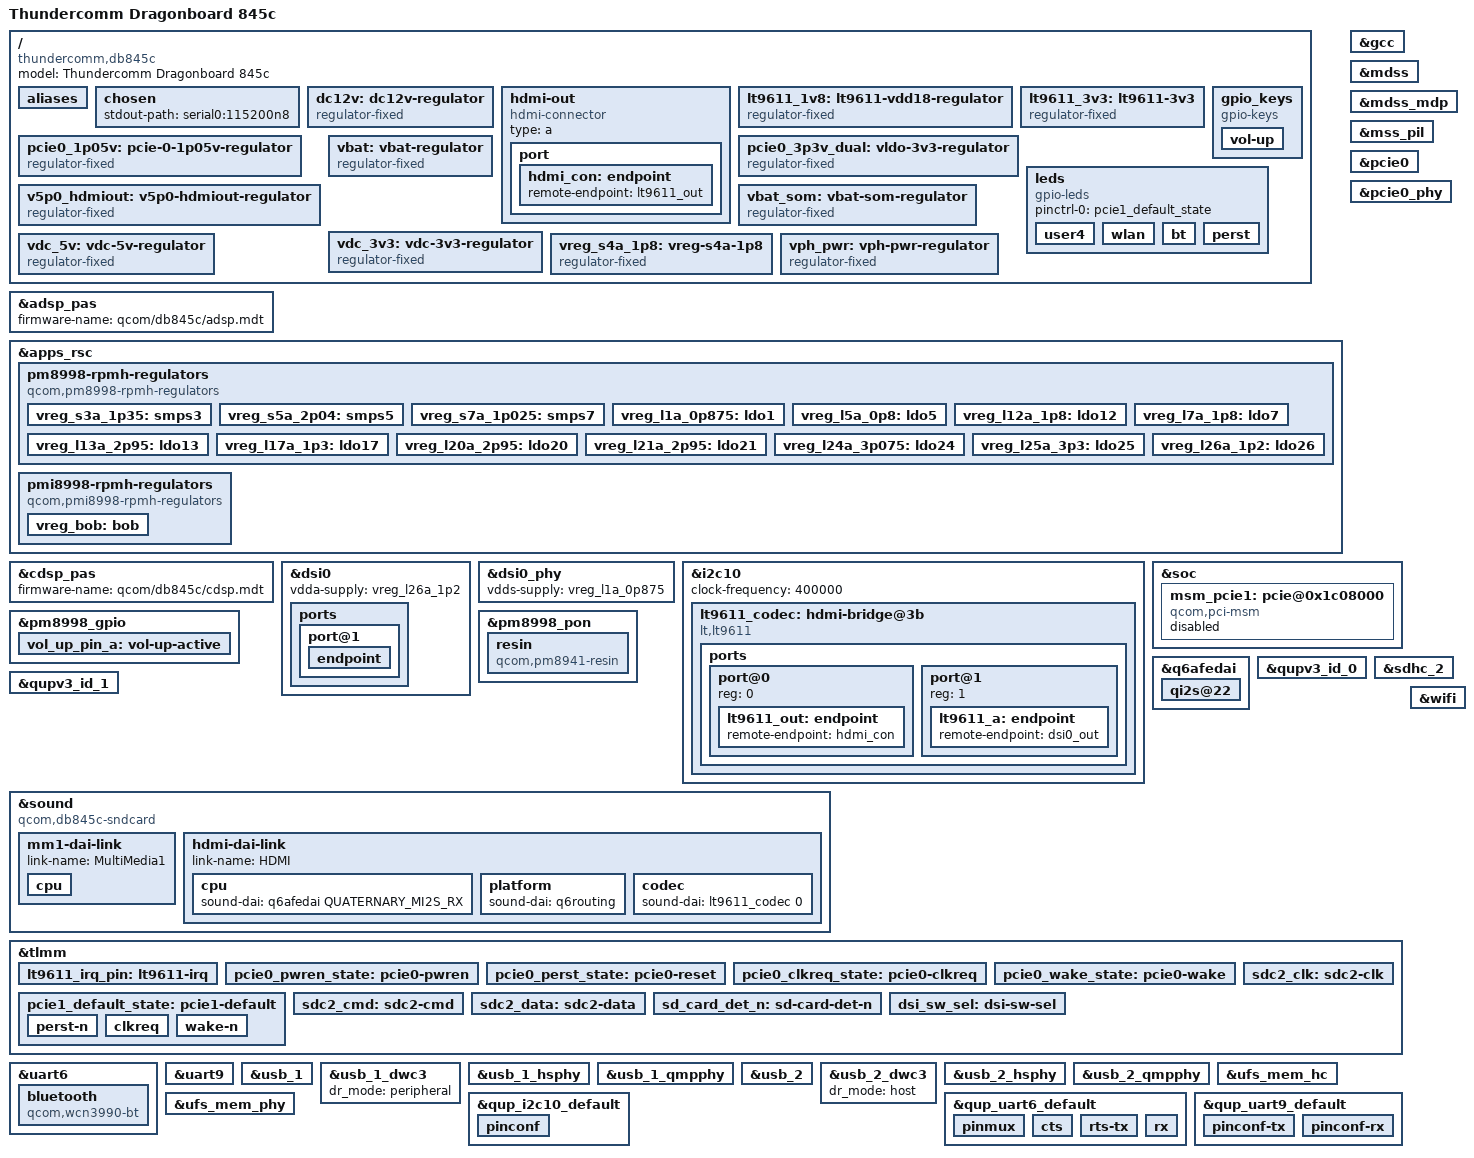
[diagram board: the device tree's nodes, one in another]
// SPDX-License-Identifier: GPL-2.0

/dts-v1/;

#include <dt-bindings/gpio/gpio.h>
#include <dt-bindings/pinctrl/qcom,pmic-gpio.h>
#include <dt-bindings/regulator/qcom,rpmh-regulator.h>
#include <dt-bindings/sound/qcom,q6afe.h>
#include <dt-bindings/sound/qcom,q6asm.h>
#include "sdm845.dtsi"
#include "pm8998.dtsi"
#include "pmi8998.dtsi"

/ {
	model = "Thundercomm Dragonboard 845c";
	compatible = "thundercomm,db845c", "qcom,sdm845";

	aliases {
		serial0 = &uart9;
		hsuart0 = &uart6;
	};

	chosen {
		stdout-path = "serial0:115200n8";
	};

	dc12v: dc12v-regulator {
		compatible = "regulator-fixed";
		regulator-name = "DC12V";
		regulator-min-microvolt = <12000000>;
		regulator-max-microvolt = <12000000>;
		regulator-always-on;
	};

	hdmi-out {
		compatible = "hdmi-connector";
		type = "a";

		port {
			hdmi_con: endpoint {
				remote-endpoint = <&lt9611_out>;
			};
		};
	};

	lt9611_1v8: lt9611-vdd18-regulator {
		compatible = "regulator-fixed";
		regulator-name = "LT9611_1V8";

		vin-supply = <&vdc_5v>;
		regulator-min-microvolt = <1800000>;
		regulator-max-microvolt = <1800000>;

		gpio = <&tlmm 89 GPIO_ACTIVE_HIGH>;
		enable-active-high;
	};

	lt9611_3v3: lt9611-3v3 {
		compatible = "regulator-fixed";
		regulator-name = "LT9611_3V3";

		vin-supply = <&vdc_3v3>;
		regulator-min-microvolt = <3300000>;
		regulator-max-microvolt = <3300000>;

		// TODO: make it possible to drive same GPIO from two clients
		// gpio = <&tlmm 89 GPIO_ACTIVE_HIGH>;
		// enable-active-high;
	};

	pcie0_1p05v: pcie-0-1p05v-regulator {
		compatible = "regulator-fixed";
		regulator-name = "PCIE0_1.05V";

		vin-supply = <&vbat>;
		regulator-min-microvolt = <1050000>;
		regulator-max-microvolt = <1050000>;

		// TODO: make it possible to drive same GPIO from two clients
		// gpio = <&tlmm 90 GPIO_ACTIVE_HIGH>;
		// enable-active-high;
	};

	pcie0_3p3v_dual: vldo-3v3-regulator {
		compatible = "regulator-fixed";
		regulator-name = "VLDO_3V3";

		vin-supply = <&vbat>;
		regulator-min-microvolt = <3300000>;
		regulator-max-microvolt = <3300000>;

		gpio = <&tlmm 90 GPIO_ACTIVE_HIGH>;
		enable-active-high;
	};

	gpio_keys {
		compatible = "gpio-keys";
		#address-cells = <1>;
		#size-cells = <0>;
		autorepeat;

		pinctrl-names = "default";
		pinctrl-0 = <&vol_up_pin_a>;

		vol-up {
			label = "Volume Up";
			linux,code = <KEY_VOLUMEUP>;
			gpios = <&pm8998_gpio 6 GPIO_ACTIVE_LOW>;
		};
	};

	leds {
		compatible = "gpio-leds";

		pinctrl-names = "default";
		pinctrl-0 = <&pcie1_default_state>;

		user4 {
			label = "db845c:green:user4";
			gpios = <&pm8998_gpio 13 GPIO_ACTIVE_HIGH>;
			linux,default-trigger = "heartbeat";
			default-state = "off";
		};

		wlan {
			label = "db845c:yellow:wlan";
			gpios = <&pm8998_gpio 9 GPIO_ACTIVE_HIGH>;
			linux,default-trigger = "phy0tx";
			default-state = "off";
		};

		bt {
			label = "db845c:blue:bt";
			gpios = <&pm8998_gpio 5 GPIO_ACTIVE_HIGH>;
			linux,default-trigger = "bluetooth-power";
			default-state = "off";
		};

		perst {
			label = "perst";
			gpios = <&tlmm 102 GPIO_ACTIVE_HIGH>;
			linux,default-trigger = "heartbeat";
			default-state = "off";
		};
	};

	v5p0_hdmiout: v5p0-hdmiout-regulator {
		compatible = "regulator-fixed";
		regulator-name = "V5P0_HDMIOUT";

		vin-supply = <&vdc_5v>;
		regulator-min-microvolt = <500000>;
		regulator-max-microvolt = <500000>;

		// TODO: make it possible to drive same GPIO from two clients
		// gpio = <&tlmm 89 GPIO_ACTIVE_HIGH>;
		// enable-active-high;
	};

	vbat: vbat-regulator {
		compatible = "regulator-fixed";
		regulator-name = "VBAT";

		vin-supply = <&dc12v>;
		regulator-min-microvolt = <4200000>;
		regulator-max-microvolt = <4200000>;
		regulator-always-on;
	};

	vbat_som: vbat-som-regulator {
		compatible = "regulator-fixed";
		regulator-name = "VBAT_SOM";

		vin-supply = <&dc12v>;
		regulator-min-microvolt = <4200000>;
		regulator-max-microvolt = <4200000>;
		regulator-always-on;
	};

	vdc_3v3: vdc-3v3-regulator {
		compatible = "regulator-fixed";
		regulator-name = "VDC_3V3";
		vin-supply = <&dc12v>;
		regulator-min-microvolt = <3300000>;
		regulator-max-microvolt = <3300000>;
		regulator-always-on;
	};

	vdc_5v: vdc-5v-regulator {
		compatible = "regulator-fixed";
		regulator-name = "VDC_5V";

		vin-supply = <&dc12v>;
		regulator-min-microvolt = <500000>;
		regulator-max-microvolt = <500000>;
		regulator-always-on;
	};

	vreg_s4a_1p8: vreg-s4a-1p8 {
		compatible = "regulator-fixed";
		regulator-name = "vreg_s4a_1p8";

		regulator-min-microvolt = <1800000>;
		regulator-max-microvolt = <1800000>;
		regulator-always-on;
	};

	vph_pwr: vph-pwr-regulator {
		compatible = "regulator-fixed";
		regulator-name = "vph_pwr";

		vin-supply = <&vbat_som>;
	};
};

&adsp_pas {
	status = "okay";
	firmware-name = "qcom/db845c/adsp.mdt";
};

&apps_rsc {
	pm8998-rpmh-regulators {
		compatible = "qcom,pm8998-rpmh-regulators";
		qcom,pmic-id = "a";
		vdd-s1-supply = <&vph_pwr>;
		vdd-s2-supply = <&vph_pwr>;
		vdd-s3-supply = <&vph_pwr>;
		vdd-s4-supply = <&vph_pwr>;
		vdd-s5-supply = <&vph_pwr>;
		vdd-s6-supply = <&vph_pwr>;
		vdd-s7-supply = <&vph_pwr>;
		vdd-s8-supply = <&vph_pwr>;
		vdd-s9-supply = <&vph_pwr>;
		vdd-s10-supply = <&vph_pwr>;
		vdd-s11-supply = <&vph_pwr>;
		vdd-s12-supply = <&vph_pwr>;
		vdd-s13-supply = <&vph_pwr>;
		vdd-l1-l27-supply = <&vreg_s7a_1p025>;
		vdd-l2-l8-l17-supply = <&vreg_s3a_1p35>;
		vdd-l3-l11-supply = <&vreg_s7a_1p025>;
		vdd-l4-l5-supply = <&vreg_s7a_1p025>;
		vdd-l6-supply = <&vph_pwr>;
		vdd-l7-l12-l14-l15-supply = <&vreg_s5a_2p04>;
		vdd-l9-supply = <&vreg_bob>;
		vdd-l10-l23-l25-supply = <&vreg_bob>;
		vdd-l13-l19-l21-supply = <&vreg_bob>;
		vdd-l16-l28-supply = <&vreg_bob>;
		vdd-l18-l22-supply = <&vreg_bob>;
		vdd-l20-l24-supply = <&vreg_bob>;
		vdd-l26-supply = <&vreg_s3a_1p35>;
		vin-lvs-1-2-supply = <&vreg_s4a_1p8>;

		vreg_s3a_1p35: smps3 {
			regulator-min-microvolt = <1352000>;
			regulator-max-microvolt = <1352000>;
		};

		vreg_s5a_2p04: smps5 {
			regulator-min-microvolt = <1904000>;
			regulator-max-microvolt = <2040000>;
		};

		vreg_s7a_1p025: smps7 {
			regulator-min-microvolt = <900000>;
			regulator-max-microvolt = <1028000>;
		};

		vreg_l1a_0p875: ldo1 {
			regulator-min-microvolt = <880000>;
			regulator-max-microvolt = <880000>;
			regulator-initial-mode = <RPMH_REGULATOR_MODE_HPM>;
		};

		vreg_l5a_0p8: ldo5 {
			regulator-min-microvolt = <800000>;
			regulator-max-microvolt = <800000>;
			regulator-initial-mode = <RPMH_REGULATOR_MODE_HPM>;
		};

		vreg_l12a_1p8: ldo12 {
			regulator-min-microvolt = <1800000>;
			regulator-max-microvolt = <1800000>;
			regulator-initial-mode = <RPMH_REGULATOR_MODE_HPM>;
		};

		vreg_l7a_1p8: ldo7 {
			regulator-min-microvolt = <1800000>;
			regulator-max-microvolt = <1800000>;
			regulator-initial-mode = <RPMH_REGULATOR_MODE_HPM>;
		};

		vreg_l13a_2p95: ldo13 {
			regulator-min-microvolt = <1800000>;
			regulator-max-microvolt = <2960000>;
			regulator-initial-mode = <RPMH_REGULATOR_MODE_HPM>;
		};

		vreg_l17a_1p3: ldo17 {
			regulator-min-microvolt = <1304000>;
			regulator-max-microvolt = <1304000>;
			regulator-initial-mode = <RPMH_REGULATOR_MODE_HPM>;
		};

		vreg_l20a_2p95: ldo20 {
			regulator-min-microvolt = <2960000>;
			regulator-max-microvolt = <2968000>;
			regulator-initial-mode = <RPMH_REGULATOR_MODE_HPM>;
		};

		vreg_l21a_2p95: ldo21 {
			regulator-min-microvolt = <2960000>;
			regulator-max-microvolt = <2968000>;
			regulator-initial-mode = <RPMH_REGULATOR_MODE_HPM>;
		};

		vreg_l24a_3p075: ldo24 {
			regulator-min-microvolt = <3088000>;
			regulator-max-microvolt = <3088000>;
			regulator-initial-mode = <RPMH_REGULATOR_MODE_HPM>;
		};

		vreg_l25a_3p3: ldo25 {
			regulator-min-microvolt = <3300000>;
			regulator-max-microvolt = <3312000>;
			regulator-initial-mode = <RPMH_REGULATOR_MODE_HPM>;
		};

		vreg_l26a_1p2: ldo26 {
			regulator-min-microvolt = <1200000>;
			regulator-max-microvolt = <1200000>;
			regulator-initial-mode = <RPMH_REGULATOR_MODE_HPM>;
		};
	};

	pmi8998-rpmh-regulators {
		compatible = "qcom,pmi8998-rpmh-regulators";
		qcom,pmic-id = "b";

		vdd-bob-supply = <&vph_pwr>;

		vreg_bob: bob {
			regulator-min-microvolt = <3312000>;
			regulator-max-microvolt = <3600000>;
			regulator-initial-mode = <RPMH_REGULATOR_MODE_AUTO>;
			regulator-allow-bypass;
		};
	};
};

&cdsp_pas {
	status = "okay";
	firmware-name = "qcom/db845c/cdsp.mdt";
};

&dsi0 {
	status = "okay";
	vdda-supply = <&vreg_l26a_1p2>;

#if 0
	qcom,dual-dsi-mode;
	qcom,master-dsi;
#endif

	ports {
		port@1 {
			endpoint {
				remote-endpoint = <&lt9611_a>;
				data-lanes = <0 1 2 3>;
			};
		};
	};
};

&dsi0_phy {
	status = "okay";
	vdds-supply = <&vreg_l1a_0p875>;
};

#if 0
&dsi1 {
	status = "okay";
	vdda-supply = <&vreg_l26a_1p2>;

	qcom,dual-dsi-mode;

	ports {
		port@1 {
			endpoint {
				remote-endpoint = <&lt9611_b>;
				data-lanes = <0 1 2 3>;
			};
		};
	};
};

&dsi1_phy {
	status = "okay";
	vdds-supply = <&vreg_l1a_0p875>;
};
#endif

&gcc {
	protected-clocks = <GCC_QSPI_CORE_CLK>,
			   <GCC_QSPI_CORE_CLK_SRC>,
			   <GCC_QSPI_CNOC_PERIPH_AHB_CLK>;
};

&i2c10 {
	status = "okay";
	clock-frequency = <400000>;

	lt9611_codec: hdmi-bridge@3b {
		compatible = "lt,lt9611";
		reg = <0x3b>;
		#sound-dai-cells = <1>;

		interrupts-extended = <&tlmm 84 IRQ_TYPE_EDGE_FALLING>;

		reset-gpios = <&tlmm 128 GPIO_ACTIVE_HIGH>;

		vdd-supply = <&lt9611_1v8>;
		vcc-supply = <&lt9611_3v3>;

		pinctrl-names = "default";
		pinctrl-0 = <&lt9611_irq_pin>, <&dsi_sw_sel>;

		ports {
			#address-cells = <1>;
			#size-cells = <0>;

			port@0 {
				reg = <0>;

				lt9611_out: endpoint {
					remote-endpoint = <&hdmi_con>;
				};
			};

			port@1 {
				reg = <1>;

				lt9611_a: endpoint {
					remote-endpoint = <&dsi0_out>;
				};
			};

#if 0
			port@2 {
				reg = <2>;

				lt9611_b: endpoint {
					remote-endpoint = <&dsi1_out>;
				};
			};
#endif
		};
	};
};

&mdss {
	status = "okay";
};

&mdss_mdp {
	status = "okay";
};

&mss_pil {
	status = "okay";
	firmware-name = "qcom/db845c/mba.mbn", "qcom/db845c/modem.mdt";
};

&pcie0 {
	status = "okay";
	perst-gpio = <&tlmm 35 GPIO_ACTIVE_LOW>;
	enable-gpio = <&tlmm 134 GPIO_ACTIVE_HIGH>;

	vddpe-3v3-supply = <&pcie0_3p3v_dual>;

	pinctrl-names = "default";
	pinctrl-0 = <&pcie0_perst_state>, <&pcie0_clkreq_state>, <&pcie0_wake_state>;

	vddpe-3v3-supply = <&pcie0_3p3v_dual>;
};

&pcie0_phy {
	status = "okay";

	vdda-phy-supply = <&vreg_l1a_0p875>;
	vdda-pll-supply = <&vreg_l26a_1p2>;
};

&soc {
	msm_pcie1: pcie@0x1c08000 {
		compatible = "qcom,pci-msm";
		cell-index = <1>;

		reg = <0 0x1c08000 0 0x2000>,
		      <0 0x1c0a000 0 0x2000>,
		      <0 0x40000000 0 0xf1d>,
		      <0 0x40000f20 0 0xa8>,
		      <0 0x40100000 0 0x100000>,
		      <0 0x40200000 0 0x100000>,
		      <0 0x40300000 0 0x1fd00000>;

		reg-names = "parf", "phy", "dm_core", "elbi",
				"conf", "io", "bars";

		#address-cells = <3>;
		#size-cells = <2>;
		ranges = <0 0x01000000 0x0 0x40200000 0x40200000 0x0 0x100000>,
			<0 0x02000000 0x0 0x40300000 0x40300000 0x0 0x1fd00000>;
		interrupt-parent = <&msm_pcie1>;
		interrupts = <0 1 2 3 4 5 6 7 8 9 10 11 12 13 14 15 16 17 18 19
				20 21 22 23 24 25 26 27 28 29 30 31 32 33 34 35
				36 37>;
		#interrupt-cells = <1>;
		interrupt-map-mask = <0 0 0 0xffffffff>;
		interrupt-map = <0 0 0 0 &intc 0 307 0
				0 0 0 1 &intc 0 434 0
				0 0 0 2 &intc 0 435 0
				0 0 0 3 &intc 0 438 0
				0 0 0 4 &intc 0 439 0
				0 0 0 5 &intc 0 306 0
				0 0 0 6 &intc 0 704 0
				0 0 0 7 &intc 0 705 0
				0 0 0 8 &intc 0 706 0
				0 0 0 9 &intc 0 707 0
				0 0 0 10 &intc 0 708 0
				0 0 0 11 &intc 0 709 0
				0 0 0 12 &intc 0 710 0
				0 0 0 13 &intc 0 711 0
				0 0 0 14 &intc 0 712 0
				0 0 0 15 &intc 0 713 0
				0 0 0 16 &intc 0 714 0
				0 0 0 17 &intc 0 715 0
				0 0 0 18 &intc 0 716 0
				0 0 0 19 &intc 0 717 0
				0 0 0 20 &intc 0 718 0
				0 0 0 21 &intc 0 719 0
				0 0 0 22 &intc 0 720 0
				0 0 0 23 &intc 0 721 0
				0 0 0 24 &intc 0 722 0
				0 0 0 25 &intc 0 723 0
				0 0 0 26 &intc 0 724 0
				0 0 0 27 &intc 0 725 0
				0 0 0 28 &intc 0 726 0
				0 0 0 29 &intc 0 727 0
				0 0 0 30 &intc 0 728 0
				0 0 0 31 &intc 0 729 0
				0 0 0 32 &intc 0 730 0
				0 0 0 33 &intc 0 731 0
				0 0 0 34 &intc 0 732 0
				0 0 0 35 &intc 0 733 0
				0 0 0 36 &intc 0 734 0
				0 0 0 37 &intc 0 735 0>;

		interrupt-names = "int_msi", "int_a", "int_b", "int_c",
				"int_d", "int_global_int",
				"msi_0", "msi_1", "msi_2", "msi_3",
				"msi_4", "msi_5", "msi_6", "msi_7",
				"msi_8", "msi_9", "msi_10", "msi_11",
				"msi_12", "msi_13", "msi_14", "msi_15",
				"msi_16", "msi_17", "msi_18", "msi_19",
				"msi_20", "msi_21", "msi_22", "msi_23",
				"msi_24", "msi_25", "msi_26", "msi_27",
				"msi_28", "msi_29", "msi_30", "msi_31";

		qcom,phy-sequence = <0x1804 0x03 0x0
					0x00dc 0x27 0x0
					0x0014 0x01 0x0
					0x0020 0x31 0x0
					0x0024 0x01 0x0
					0x0028 0xde 0x0
					0x002c 0x07 0x0
					0x0034 0x4c 0x0
					0x0038 0x06 0x0
					0x0054 0x18 0x0
					0x0058 0xb0 0x0
					0x006c 0x8c 0x0
					0x0070 0x20 0x0
					0x0078 0x14 0x0
					0x007c 0x34 0x0
					0x00b4 0x06 0x0
					0x00b8 0x06 0x0
					0x00c0 0x16 0x0
					0x00c4 0x16 0x0
					0x00cc 0x36 0x0
					0x00d0 0x36 0x0
					0x00f0 0x05 0x0
					0x00f8 0x42 0x0
					0x0100 0x82 0x0
					0x0108 0x68 0x0
					0x011c 0x55 0x0
					0x0120 0x55 0x0
					0x0124 0x03 0x0
					0x0128 0xab 0x0
					0x012c 0xaa 0x0
					0x0130 0x02 0x0
					0x0150 0x3f 0x0
					0x0158 0x3f 0x0
					0x0178 0x10 0x0
					0x01cc 0x04 0x0
					0x01d0 0x30 0x0
					0x01e0 0x04 0x0
					0x01e8 0x73 0x0
					0x01f0 0x0c 0x0
					0x01fc 0x15 0x0
					0x021c 0x04 0x0
					0x0224 0x01 0x0
					0x0228 0x22 0x0
					0x022c 0x00 0x0
					0x0098 0x20 0x0
					0x01c8 0x07 0x0
					0x080c 0x00 0x0
					0x0818 0x0d 0x0
					0x0860 0x01 0x0
					0x0864 0x1a 0x0
					0x087c 0x2f 0x0
					0x08c0 0x09 0x0
					0x08c4 0x09 0x0
					0x08c8 0x1b 0x0
					0x08d0 0x01 0x0
					0x08d4 0x07 0x0
					0x08d8 0x31 0x0
					0x08dc 0x31 0x0
					0x08e0 0x03 0x0
					0x08fc 0x02 0x0
					0x0900 0x00 0x0
					0x0908 0x12 0x0
					0x0914 0x25 0x0
					0x0918 0x00 0x0
					0x091c 0x05 0x0
					0x0920 0x01 0x0
					0x0924 0x26 0x0
					0x0928 0x12 0x0
					0x0930 0x04 0x0
					0x0934 0x04 0x0
					0x0938 0x09 0x0
					0x0954 0x15 0x0
					0x0960 0x28 0x0
					0x0968 0x7f 0x0
					0x096c 0x07 0x0
					0x0978 0x04 0x0
					0x0980 0x70 0x0
					0x0984 0x8b 0x0
					0x0988 0x08 0x0
					0x098c 0x0a 0x0
					0x0990 0x03 0x0
					0x0994 0x04 0x0
					0x0998 0x04 0x0
					0x099c 0x0c 0x0
					0x09a4 0x02 0x0
					0x09c0 0x5c 0x0
					0x09c4 0x3e 0x0
					0x09c8 0x3f 0x0
					0x0a30 0x01 0x0
					0x0a34 0xa0 0x0
					0x0a38 0x08 0x0
					0x0aa4 0x01 0x0
					0x0aac 0xc3 0x0
					0x0ab0 0x00 0x0
					0x0ab8 0xbc 0x0
					0x0ac0 0x7f 0x0
					0x0ac4 0x15 0x0
					0x0810 0x0c 0x0
					0x0814 0x0f 0x0
					0x0acc 0x04 0x0
					0x093c 0x20 0x0
					0x195c 0x3f 0x0
					0x1974 0x50 0x0
					0x182c 0x19 0x0
					0x1840 0x07 0x0
					0x1854 0x17 0x0
					0x1868 0x09 0x0
					0x196c 0x9f 0x0
					0x1800 0x00 0x0
					0x0aa8 0x01 0x0
					0x1808 0x01 0x0>;

		pinctrl-names = "default";
		pinctrl-0 = <&pcie1_default_state>;

		status = "disabled";

		perst-gpio = <&tlmm 102 0>;
		/*wake-gpio = <&tlmm 104 0>;*/

		power-domains = <&gcc PCIE_1_GDSC>;

		vreg-1.8-supply = <&vreg_l26a_1p2>;
		vreg-0.9-supply = <&vreg_l1a_0p875>;
		// vreg-cx-supply = <&pm8998_s9_level>;

		qcom,vreg-1.8-voltage-level = <1200000 1200000 24000>;
		qcom,vreg-0.9-voltage-level = <880000 880000 24000>;
//		qcom,vreg-cx-voltage-level = <RPMH_REGULATOR_LEVEL_MAX
//						RPMH_REGULATOR_LEVEL_NOM 0>;

		qcom,l1-supported;
		qcom,l1ss-supported;
		qcom,aux-clk-sync;

		qcom,ep-latency = <1000>;

		qcom,slv-addr-space-size = <0x20000000>;

		qcom,phy-status-offset = <0x1aac>;

		qcom,boot-option = <0x0>;

		linux,pci-domain = <1>;

		qcom,msi-gicm-addr = <0x17a00040>;
		qcom,msi-gicm-base = <0x2e0>;

		qcom,max-link-speed = <0x3>;

		qcom,use-19p2mhz-aux-clk;

		qcom,smmu-sid-base = <0x1c00>;

		iommu-map = <0x0 &apps_smmu 0x1c00 0x1>,
			<0x100 &apps_smmu 0x1c01 0x1>,
			<0x200 &apps_smmu 0x1c02 0x1>,
			<0x300 &apps_smmu 0x1c03 0x1>,
			<0x400 &apps_smmu 0x1c04 0x1>,
			<0x500 &apps_smmu 0x1c05 0x1>,
			<0x600 &apps_smmu 0x1c06 0x1>,
			<0x700 &apps_smmu 0x1c07 0x1>,
			<0x800 &apps_smmu 0x1c08 0x1>,
			<0x900 &apps_smmu 0x1c09 0x1>,
			<0xa00 &apps_smmu 0x1c0a 0x1>,
			<0xb00 &apps_smmu 0x1c0b 0x1>,
			<0xc00 &apps_smmu 0x1c0c 0x1>,
			<0xd00 &apps_smmu 0x1c0d 0x1>,
			<0xe00 &apps_smmu 0x1c0e 0x1>,
			<0xf00 &apps_smmu 0x1c0f 0x1>;

		qcom,msm-bus,name = "pcie1";
		qcom,msm-bus,num-cases = <2>;
		qcom,msm-bus,num-paths = <1>;
		qcom,msm-bus,vectors-KBps =
				<100 512 0 0>,
				<100 512 500 800>;

		clocks = <&gcc GCC_PCIE_1_PIPE_CLK>,
			<&rpmhcc RPMH_CXO_CLK>,
			<&gcc GCC_PCIE_1_AUX_CLK>,
			<&gcc GCC_PCIE_1_CFG_AHB_CLK>,
			<&gcc GCC_PCIE_1_MSTR_AXI_CLK>,
			<&gcc GCC_PCIE_1_SLV_AXI_CLK>,
			<&gcc GCC_PCIE_1_CLKREF_CLK>,
			<&gcc GCC_PCIE_1_SLV_Q2A_AXI_CLK>,
			<&gcc GCC_AGGRE_NOC_PCIE_TBU_CLK>,
			<&gcc GCC_PCIE_PHY_REFGEN_CLK>,
			<&gcc GCC_PCIE_PHY_AUX_CLK>;

		clock-names = "pcie_1_pipe_clk", "pcie_1_ref_clk_src",
				"pcie_1_aux_clk", "pcie_1_cfg_ahb_clk",
				"pcie_1_mstr_axi_clk", "pcie_1_slv_axi_clk",
				"pcie_1_ldo", "pcie_1_slv_q2a_axi_clk",
				"pcie_tbu_clk", "pcie_phy_refgen_clk",
				"pcie_phy_aux_clk";

		max-clock-frequency-hz = <0>, <0>, <19200000>, <0>, <0>, <0>,
					<0>, <0>, <0>, <0>, <100000000>, <0>;

		resets = <&gcc GCC_PCIE_1_BCR>,
			<&gcc GCC_PCIE_1_PHY_BCR>;

		reset-names = "pcie_1_core_reset",
				"pcie_1_phy_reset";
	};
};

&pm8998_gpio {
	vol_up_pin_a: vol-up-active {
		pins = "gpio6";
		function = "normal";
		input-enable;
		bias-pull-up;
		qcom,drive-strength = <PMIC_GPIO_STRENGTH_NO>;
	};
};

&pm8998_pon {
	resin {
		compatible = "qcom,pm8941-resin";
		interrupts = <0x0 0x8 1 IRQ_TYPE_EDGE_BOTH>;
		debounce = <15625>;
		bias-pull-up;
		linux,code = <KEY_VOLUMEDOWN>;
	};
};

/* QUAT I2S Uses 4 I2S SD Lines for audio on LT9611 HDMI Bridge */
&q6afedai {
	qi2s@22 {
		reg = <22>;
		qcom,sd-lines = <0 1 2 3>;
	};
};

&qupv3_id_0 {
	status = "okay";
};

&qupv3_id_1 {
	status = "okay";
};

&sdhc_2 {
	status = "okay";

	pinctrl-names = "default";
	pinctrl-0 = <&sdc2_clk &sdc2_cmd &sdc2_data &sd_card_det_n>;

	vmmc-supply = <&vreg_l21a_2p95>;
	vqmmc-supply = <&vreg_l13a_2p95>;

	bus-width = <4>;
	cd-gpios = <&tlmm 126 GPIO_ACTIVE_LOW>;
};

&sound {
	compatible = "qcom,db845c-sndcard";
	pinctrl-0 = <&quat_mi2s_active &quat_mi2s_sd0_active &quat_mi2s_sd1_active &quat_mi2s_sd2_active &quat_mi2s_sd3_active>;
	pinctrl-names = "default";
	model = "DB845c";

	mm1-dai-link {
		link-name = "MultiMedia1";
		cpu {
			sound-dai = <&q6asmdai  MSM_FRONTEND_DAI_MULTIMEDIA1>;
		};
	};

	hdmi-dai-link {
		link-name = "HDMI";
		cpu {
			sound-dai = <&q6afedai QUATERNARY_MI2S_RX>;
		};

		platform {
			sound-dai = <&q6routing>;
		};

		codec {
			sound-dai = <&lt9611_codec 0>;
		};
	};
};

&tlmm {
	lt9611_irq_pin: lt9611-irq {
		pins = "gpio84";
		function = "gpio";
		bias-disable;
	};

	pcie0_pwren_state: pcie0-pwren {
		pins = "gpio90";
		function = "gpio";

		drive-strength = <2>;
		bias-disable;
	};

	pcie0_perst_state: pcie0-reset {
		pins = "gpio35";
		function = "gpio";

		drive-strength = <2>;
		output-low;
		bias-pull-down;
	};

	pcie0_clkreq_state: pcie0-clkreq {
		pins = "gpio36";
		function = "pci_e0";
		bias-pull-up;
	};

	pcie0_wake_state: pcie0-wake {
		pins = "gpio37";
		function = "gpio";

		drive-strength = <2>;
		bias-pull-up;
	};

	pcie1_default_state: pcie1-default {
		perst-n {
			pins = "gpio102";
			function = "gpio";

			drive-strength = <16>;
			output-high;
		};

		clkreq {
			pins = "gpio103";
			function = "pci_e1";
			bias-pull-up;
		};

		wake-n {
			pins = "gpio11";
			function = "gpio";

			drive-strenght = <2>;
			bias-pull-up;
		};
	};

	sdc2_clk: sdc2-clk {
		pins = "sdc2_clk";
		bias-disable;

		/*
		 * It seems that mmc_test reports errors if drive
		 * strength is not 16 on clk, cmd, and data pins.
		 */
		drive-strength = <16>;
	};

	sdc2_cmd: sdc2-cmd {
		pins = "sdc2_cmd";
		bias-pull-up;
		drive-strength = <10>;
	};

	sdc2_data: sdc2-data {
		pins = "sdc2_data";
		bias-pull-up;
		drive-strength = <10>;
	};

	sd_card_det_n: sd-card-det-n {
		pins = "gpio126";
		function = "gpio";
		bias-pull-up;
	};

	dsi_sw_sel: dsi-sw-sel {
		pins = "gpio120";
		function = "gpio";

		drive-strength = <2>;
		bias-disable;
		output-high;
	};
};

&uart6 {
	status = "okay";

	bluetooth {
		compatible = "qcom,wcn3990-bt";

		vddio-supply = <&vreg_s4a_1p8>;
		vddxo-supply = <&vreg_l7a_1p8>;
		vddrf-supply = <&vreg_l17a_1p3>;
		vddch0-supply = <&vreg_l25a_3p3>;
		max-speed = <3200000>;
	};
};

&uart9 {
	status = "okay";
};

&usb_1 {
	status = "okay";
};

&usb_1_dwc3 {
	dr_mode = "peripheral";
};

&usb_1_hsphy {
	status = "okay";

	vdd-supply = <&vreg_l1a_0p875>;
	vdda-pll-supply = <&vreg_l12a_1p8>;
	vdda-phy-dpdm-supply = <&vreg_l24a_3p075>;

	qcom,imp-res-offset-value = <8>;
	qcom,hstx-trim-value = <QUSB2_V2_HSTX_TRIM_21_6_MA>;
	qcom,preemphasis-level = <QUSB2_V2_PREEMPHASIS_5_PERCENT>;
	qcom,preemphasis-width = <QUSB2_V2_PREEMPHASIS_WIDTH_HALF_BIT>;
};

&usb_1_qmpphy {
	status = "okay";

	vdda-phy-supply = <&vreg_l26a_1p2>;
	vdda-pll-supply = <&vreg_l1a_0p875>;
};

&usb_2 {
	status = "okay";
};

&usb_2_dwc3 {
	dr_mode = "host";
};

&usb_2_hsphy {
	status = "okay";

	vdd-supply = <&vreg_l1a_0p875>;
	vdda-pll-supply = <&vreg_l12a_1p8>;
	vdda-phy-dpdm-supply = <&vreg_l24a_3p075>;

	qcom,imp-res-offset-value = <8>;
	qcom,hstx-trim-value = <QUSB2_V2_HSTX_TRIM_22_8_MA>;
};

&usb_2_qmpphy {
	status = "okay";

	vdda-phy-supply = <&vreg_l26a_1p2>;
	vdda-pll-supply = <&vreg_l1a_0p875>;
};

&ufs_mem_hc {
	status = "okay";

	vcc-supply = <&vreg_l20a_2p95>;
	vcc-max-microamp = <800000>;
};

&ufs_mem_phy {
	status = "okay";

	vdda-phy-supply = <&vreg_l1a_0p875>;
	vdda-pll-supply = <&vreg_l26a_1p2>;
};

&wifi {
	status = "okay";

	vdd-0.8-cx-mx-supply = <&vreg_l5a_0p8>;
	vdd-1.8-xo-supply = <&vreg_l7a_1p8>;
	vdd-1.3-rfa-supply = <&vreg_l17a_1p3>;
	vdd-3.3-ch0-supply = <&vreg_l25a_3p3>;
};

/* PINCTRL - additions to nodes defined in sdm845.dtsi */

&qup_i2c10_default {
	pinconf {
		pins = "gpio55", "gpio56";
		drive-strength = <2>;
		bias-disable;
	};
};

&qup_uart6_default {
	pinmux {
		pins = "gpio45", "gpio46", "gpio47", "gpio48";
		function = "qup6";
	};

	cts {
		pins = "gpio45";
		bias-disable;
	};

	rts-tx {
		pins = "gpio46", "gpio47";
		drive-strength = <2>;
		bias-disable;
	};

	rx {
		pins = "gpio48";
		bias-pull-up;
	};
};

&qup_uart9_default {
	pinconf-tx {
		pins = "gpio4";
		drive-strength = <2>;
		bias-disable;
	};

	pinconf-rx {
		pins = "gpio5";
		drive-strength = <2>;
		bias-pull-up;
	};
};
